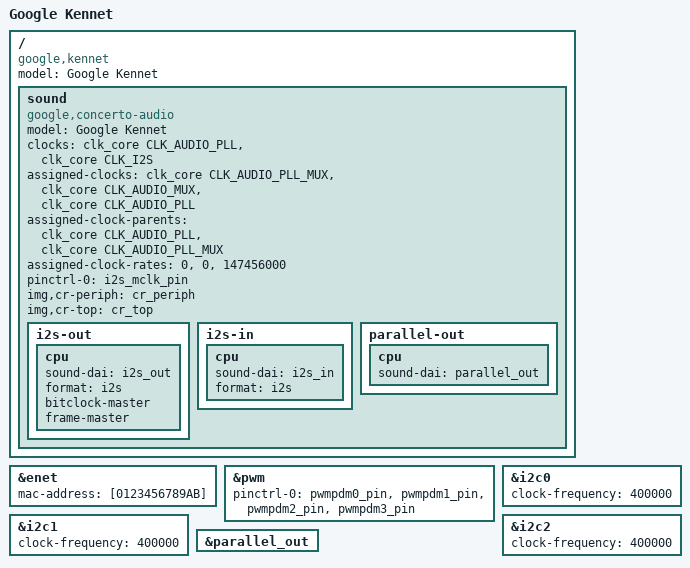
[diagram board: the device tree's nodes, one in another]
/*
 * Copyright (C) 2015 Imagination Technologies Ltd.
 * Copyright (C) 2015 Google, Inc.
 *
 * This program is free software; you can redistribute it and/or modify
 * it under the terms of the GNU General Public License version 2 as
 * published by the Free Software Foundation.
 */

/dts-v1/;

#include "pistachio_concerto.dtsi"

/ {
	model = "Google Kennet";
	compatible = "google,kennet", "google,concerto", "img,pistachio";

	sound {
		compatible = "google,concerto-audio";
		model = "Google Kennet";
		clocks = <&clk_core CLK_AUDIO_PLL>, <&clk_core CLK_I2S>;
		clock-names = "audio_pll", "mclk";
		assigned-clocks = <&clk_core CLK_AUDIO_PLL_MUX>,
				  <&clk_core CLK_AUDIO_MUX>,
				  <&clk_core CLK_AUDIO_PLL>;
		assigned-clock-parents = <&clk_core CLK_AUDIO_PLL>,
					 <&clk_core CLK_AUDIO_PLL_MUX>;
		assigned-clock-rates = <0>, <0>, <147456000>;
		pinctrl-0 = <&i2s_mclk_pin>;
		pinctrl-names = "default";

		img,cr-periph = <&cr_periph>;
		img,cr-top = <&cr_top>;

		i2s-out {
			cpu {
				sound-dai = <&i2s_out>;
				format = "i2s";
				bitclock-master;
				frame-master;
			};
		};

		i2s-in {
			cpu {
				sound-dai = <&i2s_in>;
				format = "i2s";
			};
		};

		parallel-out {
			cpu {
				sound-dai = <&parallel_out>;
			};
		};
	};
};

&enet {
	status = "okay";

	mac-address = [0123456789AB];
};

&pwm {
	status = "okay";

	pinctrl-0 = <&pwmpdm0_pin>, <&pwmpdm1_pin>, <&pwmpdm2_pin>,
		    <&pwmpdm3_pin>;
	pinctrl-names = "default";
};

&i2c0 {
	status = "okay";
	clock-frequency = <400000>;
};

&i2c1 {
	status = "okay";
	clock-frequency = <400000>;
};

&i2c2 {
	status = "okay";
	clock-frequency = <400000>;
};

&parallel_out {
	status = "okay";
};
